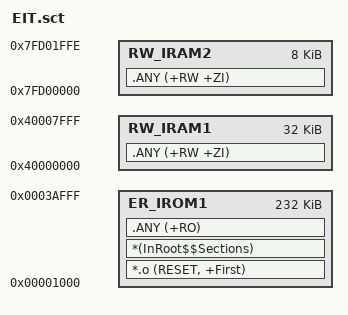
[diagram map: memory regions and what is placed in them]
; *************************************************************
; *** Scatter-Loading Description File generated by uVision ***
; *************************************************************

LR_IROM1 0x00001000 0x0003A000  {    ; load region size_region
  ER_IROM1 0x00001000 0x0003A000  {  ; load address = execution address
   *.o (RESET, +First)
   *(InRoot$$Sections)
   .ANY (+RO)
  }
  RW_IRAM1 0x40000000 0x00008000  {  ; RW data
   .ANY (+RW +ZI)
  }
  RW_IRAM2 0x7FD00000 0x00001FFF  {
   .ANY (+RW +ZI)
  }
}

